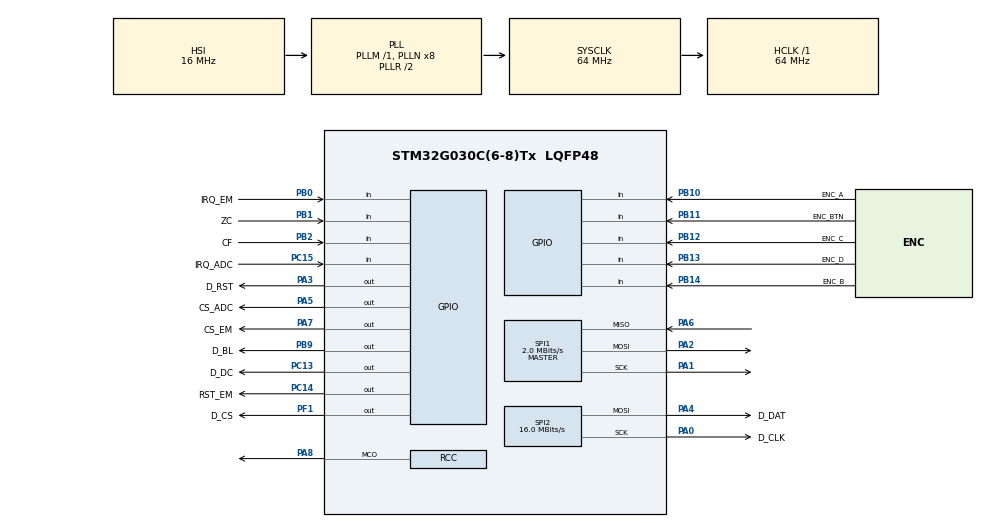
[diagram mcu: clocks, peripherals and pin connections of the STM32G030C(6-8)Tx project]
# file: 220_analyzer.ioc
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Mcu.Family=STM32G0
Mcu.Name=STM32G030C(6-8)Tx
Mcu.Package=LQFP48
PA0.GPIO_Label=D_CLK
PA0.Mode=TX_Only_Simplex_Unidirect_Master
PA0.Signal=SPI2_SCK
PA1.Mode=Full_Duplex_Master
PA1.Signal=SPI1_SCK
PA13.Mode=Serial_Wire
PA13.Signal=SYS_SWDIO
PA14-BOOT0.Mode=Serial_Wire
PA14-BOOT0.Signal=SYS_SWCLK
PA2.Mode=Full_Duplex_Master
PA2.Signal=SPI1_MOSI
PA3.GPIO_Label=D_RST
PA3.Signal=GPIO_Output
PA4.GPIO_Label=D_DAT
PA4.Mode=TX_Only_Simplex_Unidirect_Master
PA4.Signal=SPI2_MOSI
PA5.GPIO_Label=CS_ADC
PA5.PinState=GPIO_PIN_SET
PA5.Signal=GPIO_Output
PA6.Mode=Full_Duplex_Master
PA6.Signal=SPI1_MISO
PA7.GPIO_Label=CS_EM
PA7.PinState=GPIO_PIN_SET
PA7.Signal=GPIO_Output
PA8.Mode=Clock-out
PA8.Signal=RCC_MCO
PB0.GPIO_Label=IRQ_EM
PB0.Signal=GPIO_Input
PB1.GPIO_Label=ZC
PB1.Signal=GPIO_Input
PB10.GPIO_Label=ENC_A
PB10.Signal=GPIO_Input
PB11.GPIO_Label=ENC_BTN
PB11.Signal=GPIO_Input
PB12.GPIO_Label=ENC_C
PB12.Signal=GPIO_Input
PB13.GPIO_Label=ENC_D
PB13.Signal=GPIO_Input
PB14.GPIO_Label=ENC_B
PB14.Signal=GPIO_Input
PB2.GPIO_Label=CF
PB2.Signal=GPIO_Input
PB9.GPIO_Label=D_BL
PB9.Signal=GPIO_Output
PC13.GPIO_Label=D_DC
PC13.Signal=GPIO_Output
PC14-OSC32_IN\ (PC14).GPIO_Label=RST_EM
PC14-OSC32_IN\ (PC14).Signal=GPIO_Output
PC15-OSC32_OUT\ (PC15).GPIO_Label=IRQ_ADC
PC15-OSC32_OUT\ (PC15).Signal=GPIO_Input
PF1-OSC_OUT\ (PF1).GPIO_Label=D_CS
PF1-OSC_OUT\ (PF1).PinState=GPIO_PIN_SET
PF1-OSC_OUT\ (PF1).Signal=GPIO_Output
ProjectManager.HeapSize=0x200
ProjectManager.StackSize=0x400
ProjectManager.TargetToolchain=Makefile
RCC.ADCFreq_Value=64000000
RCC.AHBFreq_Value=64000000
RCC.CortexFreq_Value=64000000
RCC.EXTERNAL_CLOCK_VALUE=12288000
RCC.HCLKFreq_Value=64000000
RCC.HSE_VALUE=8000000
RCC.HSI_VALUE=16000000
RCC.LSE_VALUE=32768
RCC.RCC_MCODiv=RCC_MCODIV_16
RCC.SYSCLKFreq_VALUE=64000000
RCC.SYSCLKSource=RCC_SYSCLKSOURCE_PLLCLK
RCC.VCOOutputFreq_Value=128000000
SPI1.BaudRatePrescaler=SPI_BAUDRATEPRESCALER_32
SPI1.CalculateBaudRate=2.0 MBits/s
SPI1.Direction=SPI_DIRECTION_2LINES
SPI1.Mode=SPI_MODE_MASTER
SPI1.VirtualType=VM_MASTER
SPI2.BaudRatePrescaler=SPI_BAUDRATEPRESCALER_4
SPI2.CalculateBaudRate=16.0 MBits/s
SPI2.Direction=SPI_DIRECTION_2LINES
SPI2.Mode=SPI_MODE_MASTER
SPI2.VirtualType=VM_MASTER
TIM17.Prescaler=63
VP_TIM17_VS_ClockSourceINT.Mode=Enable_Timer
board=custom

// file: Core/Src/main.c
/* USER CODE BEGIN Header */
/**
  ******************************************************************************
  * @file           : main.c
  * @brief          : Main program body
  ******************************************************************************
  * @attention
  *
  * Copyright (c) 2023 STMicroelectronics.
  * All rights reserved.
  *
  * This software is licensed under terms that can be found in the LICENSE file
  * in the root directory of this software component.
  * If no LICENSE file comes with this software, it is provided AS-IS.
  *
  ******************************************************************************
  */
/* USER CODE END Header */
#include "main.h"

/* USER CODE BEGIN Includes */
extern void config(void);
extern void loop(void);
/* USER CODE END Includes */

SPI_HandleTypeDef hspi1;
SPI_HandleTypeDef hspi2;

TIM_HandleTypeDef htim17;

void SystemClock_Config(void);
static void MX_GPIO_Init(void);
static void MX_SPI1_Init(void);
static void MX_SPI2_Init(void);
static void MX_TIM17_Init(void);

__attribute__((noreturn)) int main(void)
{

  /* MCU Configuration--------------------------------------------------------*/

  /* Reset of all peripherals, Initializes the Flash interface and the Systick. */
  HAL_Init();

  /* Configure the system clock */
  SystemClock_Config();

  /* Initialize all configured peripherals */
  MX_GPIO_Init();
  MX_SPI1_Init();
  MX_SPI2_Init();
  MX_TIM17_Init();
  /* USER CODE BEGIN 2 */
config();
  /* USER CODE END 2 */

  /* Infinite loop */
  /* USER CODE BEGIN WHILE */
  while (1)
  {
    loop();
    /* USER CODE END WHILE */

  }
}

void SystemClock_Config(void)
{
  RCC_OscInitTypeDef RCC_OscInitStruct = {0};
  RCC_ClkInitTypeDef RCC_ClkInitStruct = {0};

  /** Configure the main internal regulator output voltage
  */
  HAL_PWREx_ControlVoltageScaling(PWR_REGULATOR_VOLTAGE_SCALE1);

  /** Initializes the RCC Oscillators according to the specified parameters
  * in the RCC_OscInitTypeDef structure.
  */
  RCC_OscInitStruct.OscillatorType = RCC_OSCILLATORTYPE_HSI;
  RCC_OscInitStruct.HSIState = RCC_HSI_ON;
  RCC_OscInitStruct.HSIDiv = RCC_HSI_DIV1;
  RCC_OscInitStruct.HSICalibrationValue = RCC_HSICALIBRATION_DEFAULT;
  RCC_OscInitStruct.PLL.PLLState = RCC_PLL_ON;
  RCC_OscInitStruct.PLL.PLLSource = RCC_PLLSOURCE_HSI;
  RCC_OscInitStruct.PLL.PLLM = RCC_PLLM_DIV1;
  RCC_OscInitStruct.PLL.PLLN = 8;
  RCC_OscInitStruct.PLL.PLLP = RCC_PLLP_DIV2;
  RCC_OscInitStruct.PLL.PLLR = RCC_PLLR_DIV2;
  if (HAL_RCC_OscConfig(&RCC_OscInitStruct) != HAL_OK)
  {
    Error_Handler();
  }

  /** Initializes the CPU, AHB and APB buses clocks
  */
  RCC_ClkInitStruct.ClockType = RCC_CLOCKTYPE_HCLK|RCC_CLOCKTYPE_SYSCLK
                              |RCC_CLOCKTYPE_PCLK1;
  RCC_ClkInitStruct.SYSCLKSource = RCC_SYSCLKSOURCE_PLLCLK;
  RCC_ClkInitStruct.AHBCLKDivider = RCC_SYSCLK_DIV1;
  RCC_ClkInitStruct.APB1CLKDivider = RCC_HCLK_DIV1;

  if (HAL_RCC_ClockConfig(&RCC_ClkInitStruct, FLASH_LATENCY_2) != HAL_OK)
  {
    Error_Handler();
  }
  HAL_RCC_MCOConfig(RCC_MCO1, RCC_MCO1SOURCE_SYSCLK, RCC_MCODIV_16);
}

static void MX_SPI1_Init(void)
{

  /* SPI1 parameter configuration*/
  hspi1.Instance = SPI1;
  hspi1.Init.Mode = SPI_MODE_MASTER;
  hspi1.Init.Direction = SPI_DIRECTION_2LINES;
  hspi1.Init.DataSize = SPI_DATASIZE_8BIT;
  hspi1.Init.CLKPolarity = SPI_POLARITY_LOW;
  hspi1.Init.CLKPhase = SPI_PHASE_1EDGE;
  hspi1.Init.NSS = SPI_NSS_SOFT;
  hspi1.Init.BaudRatePrescaler = SPI_BAUDRATEPRESCALER_32;
  hspi1.Init.FirstBit = SPI_FIRSTBIT_MSB;
  hspi1.Init.TIMode = SPI_TIMODE_DISABLE;
  hspi1.Init.CRCCalculation = SPI_CRCCALCULATION_DISABLE;
  hspi1.Init.CRCPolynomial = 7;
  hspi1.Init.CRCLength = SPI_CRC_LENGTH_DATASIZE;
  hspi1.Init.NSSPMode = SPI_NSS_PULSE_ENABLE;
  if (HAL_SPI_Init(&hspi1) != HAL_OK)
  {
    Error_Handler();
  }

}

static void MX_SPI2_Init(void)
{

  /* SPI2 parameter configuration*/
  hspi2.Instance = SPI2;
  hspi2.Init.Mode = SPI_MODE_MASTER;
  hspi2.Init.Direction = SPI_DIRECTION_2LINES;
  hspi2.Init.DataSize = SPI_DATASIZE_8BIT;
  hspi2.Init.CLKPolarity = SPI_POLARITY_LOW;
  hspi2.Init.CLKPhase = SPI_PHASE_1EDGE;
  hspi2.Init.NSS = SPI_NSS_SOFT;
  hspi2.Init.BaudRatePrescaler = SPI_BAUDRATEPRESCALER_4;
  hspi2.Init.FirstBit = SPI_FIRSTBIT_MSB;
  hspi2.Init.TIMode = SPI_TIMODE_DISABLE;
  hspi2.Init.CRCCalculation = SPI_CRCCALCULATION_DISABLE;
  hspi2.Init.CRCPolynomial = 7;
  hspi2.Init.CRCLength = SPI_CRC_LENGTH_DATASIZE;
  hspi2.Init.NSSPMode = SPI_NSS_PULSE_ENABLE;
  if (HAL_SPI_Init(&hspi2) != HAL_OK)
  {
    Error_Handler();
  }

}

static void MX_TIM17_Init(void)
{

  htim17.Instance = TIM17;
  htim17.Init.Prescaler = 63;
  htim17.Init.CounterMode = TIM_COUNTERMODE_UP;
  htim17.Init.Period = 65535;
  htim17.Init.ClockDivision = TIM_CLOCKDIVISION_DIV1;
  htim17.Init.RepetitionCounter = 0;
  htim17.Init.AutoReloadPreload = TIM_AUTORELOAD_PRELOAD_DISABLE;
  if (HAL_TIM_Base_Init(&htim17) != HAL_OK)
  {
    Error_Handler();
  }

}

static void MX_GPIO_Init(void)
{
  GPIO_InitTypeDef GPIO_InitStruct = {0};

  /* GPIO Ports Clock Enable */
  __HAL_RCC_GPIOC_CLK_ENABLE();
  __HAL_RCC_GPIOF_CLK_ENABLE();
  __HAL_RCC_GPIOA_CLK_ENABLE();
  __HAL_RCC_GPIOB_CLK_ENABLE();

  /*Configure GPIO pin Output Level */
  HAL_GPIO_WritePin(GPIOC, D_DC_Pin|RST_EM_Pin, GPIO_PIN_RESET);

  /*Configure GPIO pin Output Level */
  HAL_GPIO_WritePin(D_CS_GPIO_Port, D_CS_Pin, GPIO_PIN_SET);

  /*Configure GPIO pin Output Level */
  HAL_GPIO_WritePin(D_RST_GPIO_Port, D_RST_Pin, GPIO_PIN_RESET);

  /*Configure GPIO pin Output Level */
  HAL_GPIO_WritePin(GPIOA, CS_ADC_Pin|CS_EM_Pin, GPIO_PIN_SET);

  /*Configure GPIO pin Output Level */
  HAL_GPIO_WritePin(D_BL_GPIO_Port, D_BL_Pin, GPIO_PIN_RESET);

  /*Configure GPIO pins : D_DC_Pin RST_EM_Pin */
  GPIO_InitStruct.Pin = D_DC_Pin|RST_EM_Pin;
  GPIO_InitStruct.Mode = GPIO_MODE_OUTPUT_PP;
  GPIO_InitStruct.Pull = GPIO_NOPULL;
  GPIO_InitStruct.Speed = GPIO_SPEED_FREQ_LOW;
  HAL_GPIO_Init(GPIOC, &GPIO_InitStruct);

  /*Configure GPIO pin : IRQ_ADC_Pin */
  GPIO_InitStruct.Pin = IRQ_ADC_Pin;
  GPIO_InitStruct.Mode = GPIO_MODE_INPUT;
  GPIO_InitStruct.Pull = GPIO_NOPULL;
  HAL_GPIO_Init(IRQ_ADC_GPIO_Port, &GPIO_InitStruct);

  /*Configure GPIO pin : D_CS_Pin */
  GPIO_InitStruct.Pin = D_CS_Pin;
  GPIO_InitStruct.Mode = GPIO_MODE_OUTPUT_PP;
  GPIO_InitStruct.Pull = GPIO_NOPULL;
  GPIO_InitStruct.Speed = GPIO_SPEED_FREQ_LOW;
  HAL_GPIO_Init(D_CS_GPIO_Port, &GPIO_InitStruct);

  /*Configure GPIO pins : D_RST_Pin CS_ADC_Pin CS_EM_Pin */
  GPIO_InitStruct.Pin = D_RST_Pin|CS_ADC_Pin|CS_EM_Pin;
  GPIO_InitStruct.Mode = GPIO_MODE_OUTPUT_PP;
  GPIO_InitStruct.Pull = GPIO_NOPULL;
  GPIO_InitStruct.Speed = GPIO_SPEED_FREQ_LOW;
  HAL_GPIO_Init(GPIOA, &GPIO_InitStruct);

  /*Configure GPIO pins : IRQ_EM_Pin ZC_Pin CF_Pin ENC_A_Pin
                           ENC_BTN_Pin ENC_C_Pin ENC_D_Pin ENC_B_Pin */
  GPIO_InitStruct.Pin = IRQ_EM_Pin|ZC_Pin|CF_Pin|ENC_A_Pin
                          |ENC_BTN_Pin|ENC_C_Pin|ENC_D_Pin|ENC_B_Pin;
  GPIO_InitStruct.Mode = GPIO_MODE_INPUT;
  GPIO_InitStruct.Pull = GPIO_NOPULL;
  HAL_GPIO_Init(GPIOB, &GPIO_InitStruct);

  /*Configure GPIO pin : PA8 */
  GPIO_InitStruct.Pin = GPIO_PIN_8;
  GPIO_InitStruct.Mode = GPIO_MODE_AF_PP;
  GPIO_InitStruct.Pull = GPIO_NOPULL;
  GPIO_InitStruct.Speed = GPIO_SPEED_FREQ_LOW;
  GPIO_InitStruct.Alternate = GPIO_AF0_MCO;
  HAL_GPIO_Init(GPIOA, &GPIO_InitStruct);

  /*Configure GPIO pin : D_BL_Pin */
  GPIO_InitStruct.Pin = D_BL_Pin;
  GPIO_InitStruct.Mode = GPIO_MODE_OUTPUT_PP;
  GPIO_InitStruct.Pull = GPIO_NOPULL;
  GPIO_InitStruct.Speed = GPIO_SPEED_FREQ_LOW;
  HAL_GPIO_Init(D_BL_GPIO_Port, &GPIO_InitStruct);

}

__attribute__((noreturn)) void Error_Handler(void)
{
  __disable_irq();
  while (1)
  {
  }
}
